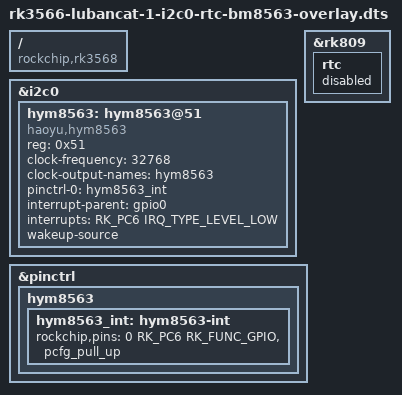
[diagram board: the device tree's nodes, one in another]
/dts-v1/;
/plugin/;

#include <dt-bindings/gpio/gpio.h>
#include <dt-bindings/pinctrl/rockchip.h>
#include <dt-bindings/interrupt-controller/irq.h>

/ {
	compatible = "rockchip,rk3568";

	fragment@0 {
		target = <&i2c0>;

		__overlay__ {
			status = "okay";
			#address-cells = <1>;
			#size-cells = <0>;

			hym8563: hym8563@51 {
				compatible = "haoyu,hym8563";
				status = "okay";
				reg = <0x51>;
				#clock-cells = <0>;
				clock-frequency = <32768>;
				clock-output-names = "hym8563";
				pinctrl-names = "default";
				pinctrl-0 = <&hym8563_int>;
				interrupt-parent = <&gpio0>;
				interrupts = <RK_PC6 IRQ_TYPE_LEVEL_LOW>;
				wakeup-source;
			};
		};
	};

	fragment@1 {
		target = <&rk809>;

		__overlay__ {
			rtc {
				status = "disabled";
			};
		};
	};

	fragment@2 {
		target = <&pinctrl>;

		__overlay__ {
			hym8563 {
				hym8563_int: hym8563-int {
					rockchip,pins = <0 RK_PC6 RK_FUNC_GPIO &pcfg_pull_up>;
				};
			};
		};
	};
};
